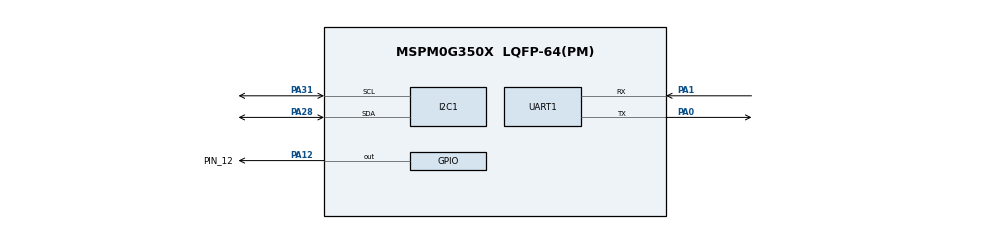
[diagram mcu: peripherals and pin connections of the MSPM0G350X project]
/**
 * @cliArgs --device "MSPM0G350X" --package "LQFP-64(PM)" --part "Default" --product "mspm0_sdk@1.30.00.03"
 * @versions {"tool":"1.19.0+3426"}
 */

/**
 * Import the modules used in this configuration.
 */
const GPIO   = scripting.addModule("/ti/driverlib/GPIO", {}, false);
const GPIO1  = GPIO.addInstance();
const I2C    = scripting.addModule("/ti/driverlib/I2C", {}, false);
const I2C1   = I2C.addInstance();
const SYSCTL = scripting.addModule("/ti/driverlib/SYSCTL");
const UART   = scripting.addModule("/ti/driverlib/UART", {}, false);
const UART1  = UART.addInstance();

/**
 * Write custom configuration values to the imported modules.
 */
const gate7  = system.clockTree["MFCLKGATE"];
gate7.enable = true;

GPIO1.port                          = "PORTA";
GPIO1.$name                         = "LED";
GPIO1.associatedPins[0].$name       = "PIN_12";
GPIO1.associatedPins[0].assignedPin = "12";
GPIO1.associatedPins[0].pin.$assign = "PA12";

const Board = scripting.addModule("/ti/driverlib/Board", {}, false);

I2C1.$name                     = "I2C_0";
I2C1.basicEnableController     = true;
I2C1.peripheral.$assign        = "I2C0";
I2C1.peripheral.sdaPin.$assign = "PA28";
I2C1.peripheral.sclPin.$assign = "PA31";
I2C1.sdaPinConfig.$name        = "ti_driverlib_gpio_GPIOPinGeneric2";
I2C1.sclPinConfig.$name        = "ti_driverlib_gpio_GPIOPinGeneric3";

SYSCTL.forceDefaultClkConfig = true;
SYSCTL.clockTreeEn           = true;

UART1.$name                    = "UART_0";
UART1.uartClkSrc               = "MFCLK";
UART1.enabledInterrupts        = ["RX"];
UART1.peripheral.$assign       = "UART0";
UART1.peripheral.rxPin.$assign = "PA1";
UART1.peripheral.txPin.$assign = "PA0";
UART1.txPinConfig.$name        = "ti_driverlib_gpio_GPIOPinGeneric0";
UART1.rxPinConfig.$name        = "ti_driverlib_gpio_GPIOPinGeneric1";

/**
 * Pinmux solution for unlocked pins/peripherals. This ensures that minor changes to the automatic solver in a future
 * version of the tool will not impact the pinmux you originally saw.  These lines can be completely deleted in order to
 * re-solve from scratch.
 */
Board.peripheral.$suggestSolution          = "DEBUGSS";
Board.peripheral.swclkPin.$suggestSolution = "PA20";
Board.peripheral.swdioPin.$suggestSolution = "PA19";
